AUTOSAR XML (schema 00051)
standard types defined: boolean, float32, float64, sint16, uint16, uint32, uint64, uint8
package /AUTOSAR/AUTOSAR_PhysicalUnits/PhysicalDimensions
  physical dimension NoDimension: length-exp=0, mass-exp=0, time-exp=0, current-exp=0, temperature-exp=0, molar-amount-exp=0, luminous-intensity-exp=0  # Dimensionless
package /AUTOSAR/AUTOSAR_PhysicalUnits/Units
  unit NoUnit: display-name=-, factor-si-to-unit=1, offset-si-to-unit=0, physical-dimension=NoDimension  # Neither Physical nor Mathematical Unit
package /SharedElements/ApplicationDataTypes/Array
  application array data type ApplicationArrayDataType_Fixed: category=ARRAY
    element Element: category=VALUE, type=ApplicationPrimitiveDataType, array-size-semantics=FIXED-SIZE, max-number-of-elements=15
  application array data type ApplicationArrayDataType_Variable: category=ARRAY, dynamic-array-size-profile=VSA_LINEAR
    element Element: category=VALUE, type=ApplicationPrimitiveDataType, array-size-handling=ALL-INDICES-SAME-ARRAY-SIZE, array-size-semantics=VARIABLE-SIZE, max-number-of-elements=15
package /SharedElements/ApplicationDataTypes/Primitive
  app type ApplicationPrimitiveDataType: category=VALUE, compu {identical}, range phys 0..7, invalid-value=8, unit=-
package /SharedElements/ApplicationDataTypes/Record
  application record data type ApplicationRecordDataType: category=STRUCTURE
    application record element Element: type=ApplicationPrimitiveDataType
    application record element Element1: type=ApplicationArrayDataType_Fixed
package /SharedElements/ConstantSpecifications
  constant specification ApplicationSwComponentType_ExplicitInterRunnableVariable: value-spec=Value:0
  constant specification ApplicationSwComponentType_SharedParameter: value-spec=Value:5.5
  constant specification ApplicationSwComponentType_StaticMemory: value-spec=Value:9
package /SharedElements/DataTypemappingSets
  data type mapping set DataTypeMappingSet
    data-type-maps:
      application-data-type=ApplicationArrayDataType_Fixed, implementation-data-type=ARRAY_ImplementationDataType
      application-data-type=ApplicationRecordDataType, implementation-data-type=STRUCTURE_ImplementationDataType1
      application-data-type=ApplicationArrayDataType_Variable, implementation-data-type=Struct_Array_ImplementationDataType
      application-data-type=ApplicationPrimitiveDataType, implementation-data-type=uint16
package /SharedElements/ImplementationDataTypes
  impl type ARRAY_ImplementationDataType: category=ARRAY
    element SubElement: array-size=15, array-size-semantics=FIXED-SIZE, implementation-data-type=uint16
  impl type STRUCTURE_ImplementationDataType1: category=STRUCTURE
    element SubElement: implementation-data-type=uint16
    element SubElement1: implementation-data-type=ARRAY_ImplementationDataType
  impl type Struct_Array_ImplementationDataType: category=STRUCTURE, dynamic-array-size-profile=VSA_LINEAR
    element SubElement1: implementation-data-type=uint8
    element SubElement: category=ARRAY
      element SubElement: array-size=15, array-size-handling=ALL-INDICES-SAME-ARRAY-SIZE, array-size-semantics=VARIABLE-SIZE, implementation-data-type=uint16
package /SharedElements/PortInterfaces/ClientServer
  client server interface ClientServerInterface
    operation Operation
      arg Argument: type=ApplicationPrimitiveDataType, direction=IN, server-argument-impl-policy=USE-ARGUMENT-TYPE
    operation Operation1
      arg Argument: type=uint8, direction=OUT, server-argument-impl-policy=USE-ARGUMENT-TYPE
package /SharedElements/PortInterfaces/ModeSwitch
  mode declaration group ModeDeclarationGroup: category=ALPHABETIC_ORDER, initial-mode=ModeDeclaration
    mode ModeDeclaration
    mode ModeDeclaration1
    mode ModeDeclaration2
  mode switch interface ModeSwitchInterface
    mode group ModeGroup: type=ModeDeclarationGroup
package /SharedElements/PortInterfaces/NvData
  nv data interface NvDataInterface
    nv-datas:
      data NvData: type=uint8
      data NvData1: type=float64
package /SharedElements/PortInterfaces/Parameter
  parameter interface ParameterInterface
    parameter data prototype Parameter: sw-calibration-access=READ-WRITE, type=float32
    parameter data prototype Parameter1: sw-calibration-access=READ-WRITE, type=uint8
package /SharedElements/PortInterfaces/SenderReceiver
  sender receiver interface SenderReceiverInterface: invalidation-policy{data-element=DataElement, handle-invalid=KEEP}
    data DataElement: sw-calibration-access=READ-WRITE, type=ApplicationPrimitiveDataType
    data DataElement1: type=uint32
package /SharedElements/PortInterfaces/Trigger
  trigger interface TriggerInterface
    trigger Trigger: trigger-period={cse-code=6, cse-code-factor=15}
package /SharedElements/SWCImpl
  swc implementation SwcImplementation: programming-language=C, sw-version=1.0.0.0, behavior=IB_Appl
    resource consumption ResourceConsumption
package /SharedElements/SwAddrMethods
  sw addr method Copy2_SwAddrMethod: memory-allocation-keyword-policy=ADDR-METHOD-SHORT-NAME, section-type=CODE
package /SwComponentTypes/ApplSWC
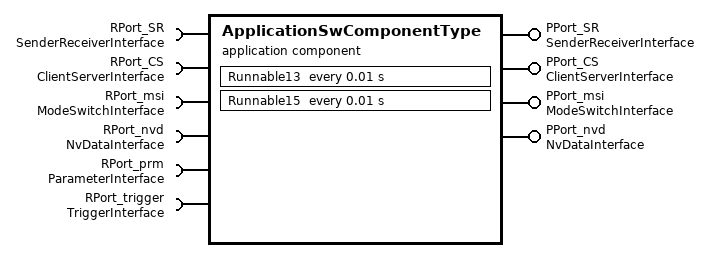
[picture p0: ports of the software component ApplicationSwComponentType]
  application sw component type ApplicationSwComponentType
    require port RPort_SR: required-interface=SenderReceiverInterface
    provide port PPort_SR: provided-interface=SenderReceiverInterface
    require port RPort_CS: required-interface=ClientServerInterface
    provide port PPort_CS: provided-interface=ClientServerInterface
    require port RPort_msi: required-interface=ModeSwitchInterface
    provide port PPort_msi: provided-interface=ModeSwitchInterface
    require port RPort_nvd: required-interface=NvDataInterface
    provide port PPort_nvd: provided-interface=NvDataInterface
    require port RPort_prm: required-interface=ParameterInterface
    require port RPort_trigger: required-interface=TriggerInterface
    behavior IB_Appl: data-type-mapping=DataTypeMappingSet, handle-termination-and-restart=NO-SUPPORT
      constant-memorys:
        parameter data prototype ConstantMemory: sw-calibration-access=READ-WRITE, type=uint64, init-value=Value:3
      static-memorys:
        data StaticMemory: type=uint8, init-value=constant-reference={short-label=ReferenceToConstant, constant=ApplicationSwComponentType_StaticMemory}
      ar-typed-per-instance-memorys:
        data ArTypedPerInstanceMemory: type=sint16, init-value=Value:-3
      asynchronous server call returns event AsynchronousServerCallReturnsEvent: start-on-event=Runnable, event-source=AsynchronousServerCallResultPoint
      background event BackgroundEvent: start-on-event=Runnable1
      data receive error event DataReceiveErrorEvent: start-on-event=Runnable2, data=RPort_SR.DataElement
      data received event DataReceivedEvent: start-on-event=Runnable3, data=RPort_SR.DataElement1
      data send completed event DataSendCompletedEvent: start-on-event=Runnable4, event-source=Runnable4/DSP_PPort_SR_DataElement
      data write completed event DataWriteCompletedEvent: start-on-event=Runnable5, event-source=Runnable5/DWA_PPort_SR_DataElement1
      external trigger occurred event ExternalTriggerOccurredEvent: start-on-event=Runnable6, trigger=RPort_trigger.Trigger
      init event InitEvent: start-on-event=Runnable7
      mode switched ack event ModeSwitchedAckEvent: start-on-event=Runnable9, event-source=Runnable9/MSP_PPort_msi_ModeGroup
      operation invoked event OperationInvokedEvent: start-on-event=Runnable10, operation=PPort_CS.Operation1
      swc mode manager error event SwcModeManagerErrorEvent: start-on-event=Runnable11, mode-group=PPort_msi.ModeGroup
      swc mode switch event SwcModeSwitchEvent: start-on-event=Runnable12, activation=ON-TRANSITION, mode=[RPort_msi.ModeGroup.ModeDeclaration2, RPort_msi.ModeGroup.ModeDeclaration]
      timing event TimingEvent: start-on-event=Runnable13, period=0.01
      transformer hard error event TransformerHardErrorEvent: start-on-event=Runnable14, required-trigger=RPort_trigger.Trigger
      timing event TimingEvent1: start-on-event=Runnable15, period=0.01
      explicit-inter-runnable-variables:
        data ExplicitInterRunnableVariable: type=boolean, init-value=constant-reference={short-label=ReferenceToConstant, constant=ApplicationSwComponentType_ExplicitInterRunnableVariable}
      implicit-inter-runnable-variables:
        data ImplicitInterRunnableVariable: type=sint16, init-value=Value:0
      per-instance-parameters:
        parameter data prototype PerInstanceParameter: sw-calibration-access=READ-WRITE, type=uint8, init-value=Value:5
      15 x runnable:
        Runnable: sw-addr-method=Copy2_SwAddrMethod, symbol=ApplicationSwComponentType_Runnable
          asynchronous server call result point AsynchronousServerCallResultPoint: asynchronous-server-call-point=ASCP_RPort_CS_Operation
          async call ASCP_RPort_CS_Operation: operation=RPort_CS.Operation, timeout=0
        Runnable{1..3}: symbol=ApplicationSwComponentType_Runnable{1..3}
        Runnable4: symbol=ApplicationSwComponentType_Runnable4
          data-send-points:
            access DSP_PPort_SR_DataElement: accessed-variable=PPort_SR.DataElement
        Runnable5: symbol=ApplicationSwComponentType_Runnable5
          data-write-access:
            access DWA_PPort_SR_DataElement1: accessed-variable=PPort_SR.DataElement1
        Runnable6: symbol=ApplicationSwComponentType_Runnable6
        Runnable7: symbol=ApplicationSwComponentType_Runnable7
        Runnable9: symbol=ApplicationSwComponentType_Runnable9
          mode switch point MSP_PPort_msi_ModeGroup: mode-group=PPort_msi.ModeGroup
        Runnable{10..12}: symbol=ApplicationSwComponentType_Runnable{10..12}
        Runnable13: symbol=ApplicationSwComponentType_Runnable13
          data-read-access:
            4 x access:
              DRA_RPort_SR_DataElement: accessed-variable=RPort_SR.DataElement
              DRA_RPort_SR_DataElement1: accessed-variable=RPort_SR.DataElement1
              DRA_RPort_nvd_NvData: accessed-variable=RPort_nvd.NvData
              DRA_RPort_nvd_NvData1: accessed-variable=RPort_nvd.NvData1
          data-write-access:
            4 x access:
              DWA_PPort_SR_DataElement: accessed-variable=PPort_SR.DataElement
              DWA_PPort_SR_DataElement1: accessed-variable=PPort_SR.DataElement1
              DWA_PPort_nvd_NvData: accessed-variable=PPort_nvd.NvData
              DWA_PPort_nvd_NvData1: accessed-variable=PPort_nvd.NvData1
          read-local-variables:
            access IRVRA_ExplicitInterRunnableVariable: accessed-variable=ExplicitInterRunnableVariable
            access IRVRA_ImplicitInterRunnableVariable: accessed-variable=ImplicitInterRunnableVariable
        Runnable14: symbol=ApplicationSwComponentType_Runnable14
        Runnable15: symbol=ApplicationSwComponentType_Runnable15
          data-read-access:
            access DRA_RPort_nvd_NvData: accessed-variable=RPort_nvd.NvData
            access DRA_RPort_nvd_NvData1: accessed-variable=RPort_nvd.NvData1
          data-receive-point-by-arguments:
            access DRP_RPort_SR_DataElement: accessed-variable=RPort_SR.DataElement
            access DRP_RPort_nvd_NvData: accessed-variable=RPort_nvd.NvData
            access DRP_RPort_nvd_NvData1: accessed-variable=RPort_nvd.NvData1
          data-receive-point-by-values:
            access DRPV_RPort_SR_DataElement1: accessed-variable=RPort_SR.DataElement1
            access DRPV_RPort_nvd_NvData: accessed-variable=RPort_nvd.NvData
          data-send-points:
            4 x access:
              DSP_PPort_SR_DataElement: accessed-variable=PPort_SR.DataElement
              DSP_PPort_SR_DataElement1: accessed-variable=PPort_SR.DataElement1
              DSP_PPort_nvd_NvData: accessed-variable=PPort_nvd.NvData
              DSP_PPort_nvd_NvData1: accessed-variable=PPort_nvd.NvData1
          data-write-access:
            access DWA_PPort_SR_DataElement1: accessed-variable=PPort_SR.DataElement1
          mode switch point MSP_PPort_msi_ModeGroup: mode-group=PPort_msi.ModeGroup
          5 x parameter access:
            ParameterAccess: accessed-parameter=ConstantMemory
            PICPVA_PerInstanceParameter: accessed-parameter=PerInstanceParameter
            CPA_RPort_prm_Parameter: accessed-parameter=RPort_prm.Parameter
            CPA_RPort_prm_Parameter1: accessed-parameter=RPort_prm.Parameter1
            SCPVA_SharedParameter: accessed-parameter=SharedParameter
          sync call SSCP_RPort_CS_Operation1: operation=RPort_CS.Operation1, timeout=0
          written-local-variables:
            access IRVWA_ExplicitInterRunnableVariable: accessed-variable=ExplicitInterRunnableVariable
            access IRVWA_ImplicitInterRunnableVariable: accessed-variable=ImplicitInterRunnableVariable
      shared-parameters:
        parameter data prototype SharedParameter: sw-calibration-access=READ-WRITE, type=float32, init-value=constant-reference={short-label=ReferenceToConstant, constant=ApplicationSwComponentType_SharedParameter}
